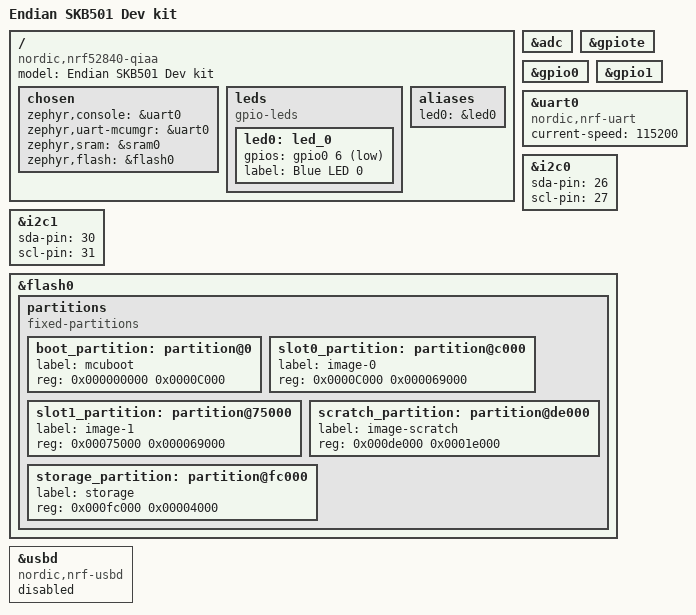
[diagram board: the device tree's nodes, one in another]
/*
 * Copyright (c) 2017 Linaro Limited
 *
 * SPDX-License-Identifier: Apache-2.0
 */

/dts-v1/;
#include <nordic/nrf52840.dtsi>

/ {
	model = "Endian SKB501 Dev kit";
	compatible = "nordic,nrf52840-qiaa",
		     "nordic,nrf52840";

	chosen {
		zephyr,console = &uart0;
		zephyr,uart-mcumgr = &uart0;
		zephyr,sram = &sram0;
		zephyr,flash = &flash0;
	};

	leds {
		compatible = "gpio-leds";
		led0: led_0 {
			gpios = <&gpio0 6 GPIO_INT_ACTIVE_LOW>;
			label = "Blue LED 0";
		};
	};

	/* These aliases are provided for compatibility with samples */
	aliases {
		led0 = &led0;
	};
};

&adc {
	status ="ok";
};

&gpiote {
	status ="ok";
};

&gpio0 {
	status ="ok";
};

&gpio1 {
	status ="ok";
};

&uart0 {
	compatible = "nordic,nrf-uart";
	current-speed = <115200>;
	status = "ok";
};

&i2c0 {
	status = "ok";
	sda-pin = <26>;
	scl-pin = <27>;
};

&i2c1 {
	status = "ok";
	sda-pin = <30>;
	scl-pin = <31>;
};

&flash0 {
	/*
	 * For more information, see:
	 * http://docs.zephyrproject.org/latest/devices/dts/flash_partitions.html
	 */
	partitions {
		compatible = "fixed-partitions";
		#address-cells = <1>;
		#size-cells = <1>;

		boot_partition: partition@0 {
			label = "mcuboot";
			reg = <0x000000000 0x0000C000>;
		};
		slot0_partition: partition@c000 {
			label = "image-0";
			reg = <0x0000C000 0x000069000>;
		};
		slot1_partition: partition@75000 {
			label = "image-1";
			reg = <0x00075000 0x000069000>;
		};
		scratch_partition: partition@de000 {
			label = "image-scratch";
			reg = <0x000de000 0x0001e000>;
		};
		storage_partition: partition@fc000 {
			label = "storage";
			reg = <0x000fc000 0x00004000>;
		};
	};
};

&usbd {
	compatible = "nordic,nrf-usbd";
	status = "disabled";
};
